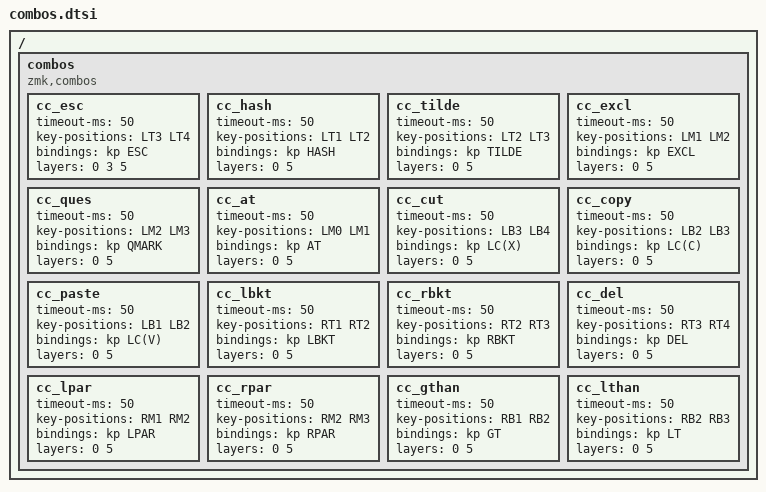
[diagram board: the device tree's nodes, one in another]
/*                KEY POSITIONS

  ╭─────────────────────╮ ╭─────────────────────╮
  │ LT4 LT3 LT2 LT1 LT0 │ │ RT0 RT1 RT2 RT3 RT4 │
  │ LM4 LM3 LM2 LM1 LM0 │ │ RM0 RM1 RM2 RM3 RM4 │
  │ LB4 LB3 LB2 LB1 LB0 │ │ RB0 RB1 RB2 RB3 RB4 │
  ╰───────╮ LH2 LH1 LH0 │ │ RH0 RH1 RH2 ╭───────╯
          ╰─────────────╯ ╰─────────────╯ */


/ {
    combos {
        compatible = "zmk,combos";

        //-----------------------------------------
        // Left Top
        
        cc_esc {
            timeout-ms = <50>;
            key-positions = <LT3 LT4>;
            bindings = <&kp ESC>;
            layers = <0 3 5>;
        };
        cc_hash {
            timeout-ms = <50>;
            key-positions = <LT1 LT2>;
            bindings = <&kp HASH>;
            layers = <0 5>;
        };
        cc_tilde {
            timeout-ms = <50>;
            key-positions = <LT2 LT3>;
            bindings = <&kp TILDE>;
            layers = <0 5>;
        };
 
        //-----------------------------------------
        // Left Mid

        cc_excl {
            timeout-ms = <50>;
            key-positions = <LM1 LM2>;
            bindings = <&kp EXCL>;
            layers = <0 5>;
        };
        cc_ques {
            timeout-ms = <50>;
            key-positions = <LM2 LM3>;
            bindings = <&kp QMARK>;
            layers = <0 5>;
        };
        cc_at {
            timeout-ms = <50>;
            key-positions = <LM0 LM1>;
            bindings = <&kp AT>;
            layers = <0 5>;
        };

        //-----------------------------------------
        // Left Bottom

        cc_cut {
            timeout-ms = <50>;
            key-positions = <LB3 LB4>;
            bindings = <&kp LC(X)>;
            layers = <0 5>;
        };        
        cc_copy {
            timeout-ms = <50>;
            key-positions = <LB2 LB3>;
            bindings = <&kp LC(C)>;
            layers = <0 5>;
        };
        cc_paste {
            timeout-ms = <50>;
            key-positions = <LB1 LB2>;
            bindings = <&kp LC(V)>;
            layers = <0 5>;
        };

        //-----------------------------------------
        // Right Top

        cc_lbkt {
            timeout-ms = <50>;
            key-positions = <RT1 RT2>;
            bindings = <&kp LBKT>;
            layers = <0 5>;
        };        
        cc_rbkt {
            timeout-ms = <50>;
            key-positions = <RT2 RT3>;
            bindings = <&kp RBKT>;
            layers = <0 5>;
        };
        cc_del {
            timeout-ms = <50>;
            key-positions = <RT3 RT4>;
            bindings = <&kp DEL>;
            layers = <0 5>;
        };

        //-----------------------------------------
        // Right Mid
        
        cc_lpar {
            timeout-ms = <50>;
            key-positions = <RM1 RM2>;
            bindings = <&kp LPAR>;
            layers = <0 5>;
        };        
        cc_rpar {
            timeout-ms = <50>;
            key-positions = <RM2 RM3>;
            bindings = <&kp RPAR>;
            layers = <0 5>;
        };

        //-----------------------------------------
        // Right Bottom

        cc_gthan {
            timeout-ms = <50>;
            key-positions = <RB1 RB2>;
            bindings = <&kp GT>;
            layers = <0 5>;
        };        
        cc_lthan {
            timeout-ms = <50>;
            key-positions = <RB2 RB3>;
            bindings = <&kp LT>;
            layers = <0 5>;
        };

        
    };
};
